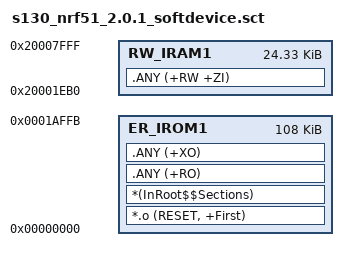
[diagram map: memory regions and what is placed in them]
; *************************************************************
; *** Scatter-Loading Description File generated by uVision ***
; *************************************************************

LR_IROM1 0x00000000 0x0001AFFC  {    ; load region size_region
  ER_IROM1 0x00000000 0x0001AFFC  {  ; load address = execution address
   *.o (RESET, +First)
   *(InRoot$$Sections)
   .ANY (+RO)
   .ANY (+XO)
  }
  RW_IRAM1 0x20001EB0 0x00006150  {  ; RW data
   .ANY (+RW +ZI)
  }
}

